# S6E1A1 register map
File version: 1.1
Registers are 8-bit, read-write, reset 0x0 unless marked. A register's access mark holds for its fields unless they carry their own. Offsets are from the block's base; [hi:lo] are bit positions; {n}, {i} and the like mark numbered series; 'fields as' and 'values as' point back to an identical list.

## LSCRP — Low-speed CR Prescaler Register
Base 0x4003C000
0x00 LCR_PRSLD — Low-speed CR Prescaler Control Register
  [5:0] LCR_PRSLD — Low-speed CR Prescaler Load

## PCG — Peripheral Clock Gating Registers
Base 0x4003C100
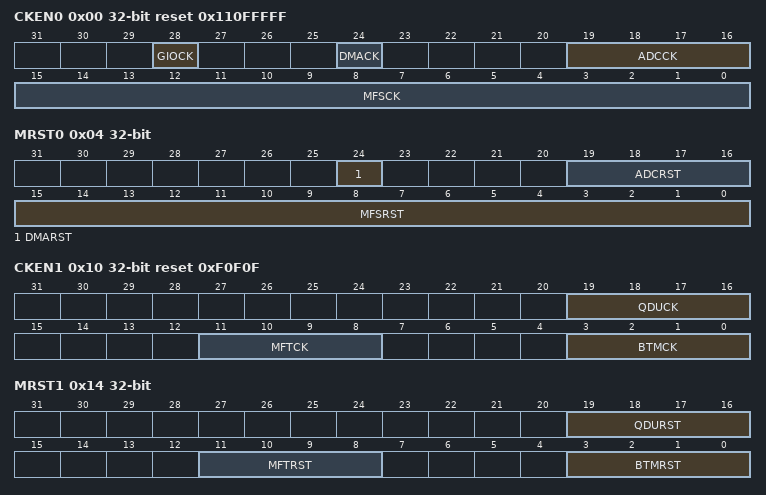
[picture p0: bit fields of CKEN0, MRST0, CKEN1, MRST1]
0x00 CKEN0 32-bit reset 0x110FFFFF — Peripheral Clock Control Register 0
  [28] GIOCK — Software clock control of GPIO/Fast GPIO function
  [24] DMACK — Supplying and gating settings of DMAC operation clock
  [19:16] ADCCK — Settings for operation clock supplying and gating to AD converter
  [15:0] MFSCK — Settings for operation clock supply and gating to multi-function serial interface
0x04 MRST0 32-bit — Peripheral Reset Control Register 0
  [24] DMARST — Reset control of DMAC
  [19:16] ADCRST — Reset control of AD converter
  [15:0] MFSRST ro — Control of software reset of multi-function serial interface
0x10 CKEN1 32-bit reset 0xF0F0F — Peripheral Clock Control Register 1
  [19:16] QDUCK — Settings for operation clock supply and gating of quad counter
  [11:8] MFTCK — Settings for operation clock supply and gating of multi-function timer and PPG
  [3:0] BTMCK — Settings operation clock supply and gating to base timer
0x14 MRST1 32-bit — Peripheral Reset Control Register 1
  [19:16] QDURST — Reset control of quad counter
  [11:8] MFTRST — Control of multi-function timer and PPG reset control
  [3:0] BTMRST — Reset control of base timer
0x20 CKEN2 32-bit reset 0x30 — Peripheral Clock Control Register 2
  [5:4] CANCK — Settings for clock supply and gating to CAN controller
0x24 MRST2 32-bit — Peripheral Reset Control Reset 2
  [5:4] CANRST — Reset control of CAN controller

## DMAC — DMAC Registers
Base 0x40060000
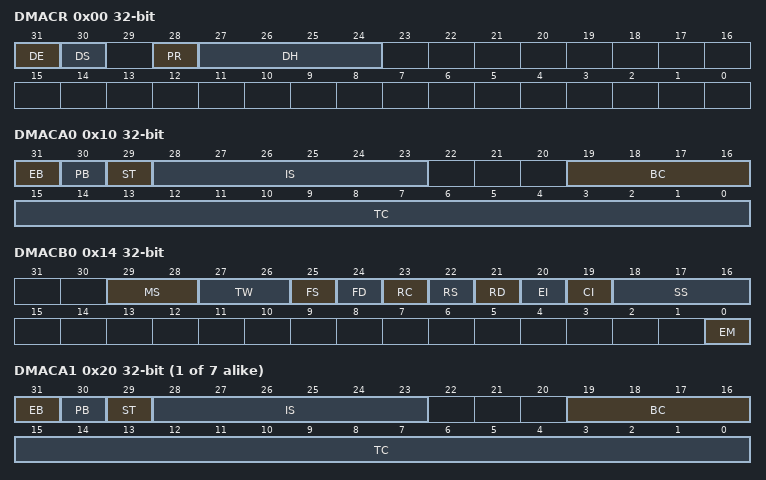
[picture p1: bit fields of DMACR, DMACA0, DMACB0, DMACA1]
0x00 DMACR 32-bit — Entire DMAC Configuration Register
  [31] DE — DMA Enable (all-channel operation enable bit)
  [30] DS — DMA Stop
  [28] PR — Priority Rotation
  [27:24] DH — DMA Halt (All-channel pause bit)
0x10 DMACA0 32-bit — Configuration A Register
  [31] EB — Enable bit (individual-channel operation enable bit)
  [30] PB — Pause bit (individual-channel pause bit)
  [29] ST — Software Trigger
  [28:23] IS — Input Select
  [19:16] BC — Block Count
  [15:0] TC — Transfer Count
0x14 DMACB0 32-bit — Configuration B Register
  [29:28] MS — Mode Select
  [27:26] TW — Transfer Width
  [25] FS — Fixed Source
  [24] FD — Fixed Destination
  [23] RC — Reload Count (BC/TC reload)
  [22] RS — Reload Source
  [21] RD — Reload Destination
  [20] EI — Error Interrupt (unsuccessful transfer completion interrupt enable)
  [19] CI — Completion Interrupt (successful transfer completion interrupt enable)
  [18:16] SS — Stop Status (stop status notification)
  [0] EM — Enable bit Mask (EB bit clear mask)
{0x18+0x10*i} DMACSA{i} 32-bit (i=0..7) — Transfer Source Address Register {i}
{0x1C+0x10*i} DMACDA{i} 32-bit (i=0..7) — Transfer Destination Address Register {i}
{0x10+0x10*i} DMACA{i} 32-bit (i=1..7) — Configuration A Register {i}
  fields as DMACA0
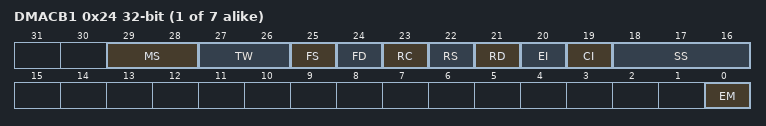
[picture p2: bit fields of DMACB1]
{0x14+0x10*i} DMACB{i} 32-bit (i=1..7) — Configuration B Register {i}
  fields as DMACB0

## MTB_DWT — Micro Trace Buffer Data Watchpoint and Trace Registers
Base 0xF0001000
0x00 CMP_ADDR_START 32-bit — MTB_DWT Address Comparison Start Trace Register
  [31:0] ADCMP_STA — MTB_DWT address comparison start trace bits
0x04 CMP_DATA_START 32-bit — MTB_DWT Data Comparison Start Trace Register
  [31:0] DTCMP_STA — MTB_DWT data comparison start trace bits
0x08 CMP_MASK_START 32-bit — MTB_DWT Data Compare Start Trace Register Mask Register
  [31:0] MSK_STA — MTB_DWT data compare start trace register mask bits
0x10 CMP_ADDR_STOP 32-bit — MTB_DWT Address Comparison Stop Trace Register
  [31:0] ADCMP_STO — MTB_DWT address comparison stop trace bits
0x14 CMP_DATA_STOP 32-bit — MTB_DWT Data Comparison Stop Trace Register
  [31:0] DTCMP_STO — MTB_DWT data comparison stop trace bits
0x18 CMP_MASK_STOP 32-bit — MTB_DWT Data Compare Stop Trace Register Mask Register
  [31:0] MSK_STO — MTB_DWT data compare stop trace register mask bits
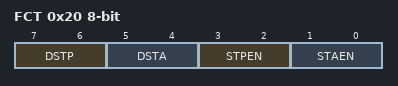
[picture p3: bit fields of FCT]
0x20 FCT — MTB_DWT Function Register
  [7:6] DSTP — Data size stop bits
  [5:4] DSTA — Data size start bits
  [3:2] STPEN — Enable MTB_DWT stop MTB function bits
  [1:0] STAEN — Enable MTB_DWT start MTB function bits
{0xFC0+4i} PID{i} 32-bit ro (i=4..7) — Peripheral ID{i} Register
  [31:0] PERID rw — Peripheral ID bits
0xFE0 PID0 32-bit ro reset 0x16 — Peripheral ID0 Register
  [31:0] PERID — Peripheral ID bits
0xFE4 PID1 32-bit ro reset 0x48 — Peripheral ID1 Register
  [31:0] PERID — Peripheral ID bits
0xFE8 PID2 32-bit ro reset 0x8 — Peripheral ID2 Register
  [31:0] PERID — Peripheral ID bits
0xFEC PID3 32-bit ro — Peripheral ID3 Register
  [31:0] PERID — Peripheral ID bits
0xFF0 CID0 32-bit ro reset 0xD — Component ID0 Register
  [31:0] CPNTID — Component ID bits
0xFF4 CID1 32-bit ro reset 0x90 — Component ID1 Register
  [31:0] CPNTID — Component ID bits
0xFF8 CID2 32-bit ro reset 0x5 — Component ID2 Register
  [31:0] CPNTID — Component ID bits
0xFFC CID3 32-bit ro reset 0xB1 — Component ID3 Register
  [31:0] CPNTID — Component ID bits
